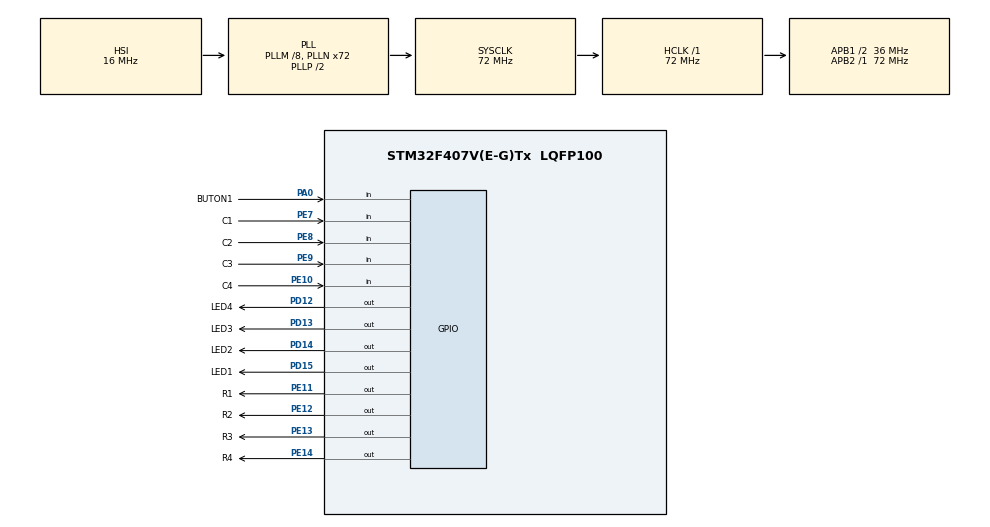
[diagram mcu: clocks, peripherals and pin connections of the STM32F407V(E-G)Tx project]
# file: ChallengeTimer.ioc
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Mcu.Family=STM32F4
Mcu.Name=STM32F407V(E-G)Tx
Mcu.Package=LQFP100
NVIC.PriorityGroup=NVIC_PRIORITYGROUP_4
NVIC.TIM2_IRQn=true\:0\:0\:false\:false\:true\:true\:true\:true
PA0-WKUP.GPIO_Label=BUTON1
PA0-WKUP.Signal=GPIO_Input
PA13.Mode=Serial_Wire
PA13.Signal=SYS_JTMS-SWDIO
PA14.Mode=Serial_Wire
PA14.Signal=SYS_JTCK-SWCLK
PD12.GPIO_Label=LED4
PD12.GPIO_Speed=GPIO_SPEED_FREQ_MEDIUM
PD12.Signal=GPIO_Output
PD13.GPIO_Label=LED3
PD13.GPIO_Speed=GPIO_SPEED_FREQ_MEDIUM
PD13.Signal=GPIO_Output
PD14.GPIO_Label=LED2
PD14.GPIO_Speed=GPIO_SPEED_FREQ_MEDIUM
PD14.Signal=GPIO_Output
PD15.GPIO_Label=LED1
PD15.GPIO_Speed=GPIO_SPEED_FREQ_MEDIUM
PD15.Signal=GPIO_Output
PE10.GPIO_Label=C4
PE10.GPIO_PuPd=GPIO_PULLDOWN
PE10.Signal=GPIO_Input
PE11.GPIO_Label=R1
PE11.GPIO_Speed=GPIO_SPEED_FREQ_MEDIUM
PE11.Signal=GPIO_Output
PE12.GPIO_Label=R2
PE12.GPIO_Speed=GPIO_SPEED_FREQ_MEDIUM
PE12.Signal=GPIO_Output
PE13.GPIO_Label=R3
PE13.GPIO_Speed=GPIO_SPEED_FREQ_MEDIUM
PE13.Signal=GPIO_Output
PE14.GPIO_Label=R4
PE14.GPIO_Speed=GPIO_SPEED_FREQ_MEDIUM
PE14.Signal=GPIO_Output
PE7.GPIO_Label=C1
PE7.GPIO_PuPd=GPIO_PULLDOWN
PE7.Signal=GPIO_Input
PE8.GPIO_Label=C2
PE8.GPIO_PuPd=GPIO_PULLDOWN
PE8.Signal=GPIO_Input
PE9.GPIO_Label=C3
PE9.GPIO_PuPd=GPIO_PULLDOWN
PE9.Signal=GPIO_Input
PH0-OSC_IN.Mode=HSE-External-Oscillator
PH0-OSC_IN.Signal=RCC_OSC_IN
PH1-OSC_OUT.Mode=HSE-External-Oscillator
PH1-OSC_OUT.Signal=RCC_OSC_OUT
ProjectManager.HeapSize=0x200
ProjectManager.StackSize=0x400
ProjectManager.TargetToolchain=STM32CubeIDE
RCC.48MHZClocksFreq_Value=36000000
RCC.AHBFreq_Value=72000000
RCC.APB1CLKDivider=RCC_HCLK_DIV2
RCC.APB1Freq_Value=36000000
RCC.APB1TimFreq_Value=72000000
RCC.APB2Freq_Value=72000000
RCC.APB2TimFreq_Value=72000000
RCC.CortexFreq_Value=72000000
RCC.HCLKFreq_Value=72000000
RCC.HSE_VALUE=25000000
RCC.HSI_VALUE=16000000
RCC.LSE_VALUE=32768
RCC.PLLM=8
RCC.PLLN=72
RCC.SYSCLKFreq_VALUE=72000000
RCC.SYSCLKSource=RCC_SYSCLKSOURCE_PLLCLK
RCC.VCOOutputFreq_Value=144000000
TIM2.Period=1000-1
TIM2.Prescaler=7200-1
VP_TIM2_VS_ClockSourceINT.Mode=Internal
board=custom

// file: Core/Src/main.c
/* USER CODE BEGIN Header */
/**
 ******************************************************************************
 * @file           : main.c
 * @brief          : Main program body
 ******************************************************************************
 * @attention
 *
 * Copyright (c) 2025 STMicroelectronics.
 * All rights reserved.
 *
 * This software is licensed under terms that can be found in the LICENSE file
 * in the root directory of this software component.
 * If no LICENSE file comes with this software, it is provided AS-IS.
 *
 ******************************************************************************
 */
/* USER CODE END Header */
#include "main.h"

/* USER CODE BEGIN Includes */
#include "keypad.h"
#include "macro.h"
#include "timer.h"
#include "mission.h"

/* USER CODE END Includes */

TIM_HandleTypeDef htim2;

void SystemClock_Config(void);
static void MX_GPIO_Init(void);
static void MX_TIM2_Init(void);
/* USER CODE BEGIN PFP */

char Read_Keypad(void);

/* USER CODE END PFP */

/* USER CODE BEGIN 0 */
char pressed_key = '\0';

/* USER CODE END 0 */

int main(void)
{

	/* USER CODE BEGIN 1 */

	//int atis_butonu=0;
	//int button_state=0;

	/* USER CODE END 1 */

	/* MCU Configuration--------------------------------------------------------*/

	/* Reset of all peripherals, Initializes the Flash interface and the Systick. */
	HAL_Init();

	/* Configure the system clock */
	SystemClock_Config();

	/* Initialize all configured peripherals */
	MX_GPIO_Init();
	MX_TIM2_Init();
	/* USER CODE BEGIN 2 */

	HAL_TIM_Base_Start_IT(&htim2);

	/* USER CODE END 2 */

	/* Infinite loop */
	while (1)
	{

		/* USER CODE BEGIN 3 */

		setFlags();
		timerMissions();
		clearFlags();

	}
	/* USER CODE END 3 */
}

void SystemClock_Config(void)
{
	RCC_OscInitTypeDef RCC_OscInitStruct = {0};
	RCC_ClkInitTypeDef RCC_ClkInitStruct = {0};

	/** Configure the main internal regulator output voltage
	 */
	__HAL_RCC_PWR_CLK_ENABLE();
	__HAL_PWR_VOLTAGESCALING_CONFIG(PWR_REGULATOR_VOLTAGE_SCALE1);

	/** Initializes the RCC Oscillators according to the specified parameters
	 * in the RCC_OscInitTypeDef structure.
	 */
	RCC_OscInitStruct.OscillatorType = RCC_OSCILLATORTYPE_HSI;
	RCC_OscInitStruct.HSIState = RCC_HSI_ON;
	RCC_OscInitStruct.HSICalibrationValue = RCC_HSICALIBRATION_DEFAULT;
	RCC_OscInitStruct.PLL.PLLState = RCC_PLL_ON;
	RCC_OscInitStruct.PLL.PLLSource = RCC_PLLSOURCE_HSI;
	RCC_OscInitStruct.PLL.PLLM = 8;
	RCC_OscInitStruct.PLL.PLLN = 72;
	RCC_OscInitStruct.PLL.PLLP = RCC_PLLP_DIV2;
	RCC_OscInitStruct.PLL.PLLQ = 4;
	if (HAL_RCC_OscConfig(&RCC_OscInitStruct) != HAL_OK)
	{
		Error_Handler();
	}

	/** Initializes the CPU, AHB and APB buses clocks
	 */
	RCC_ClkInitStruct.ClockType = RCC_CLOCKTYPE_HCLK|RCC_CLOCKTYPE_SYSCLK
			|RCC_CLOCKTYPE_PCLK1|RCC_CLOCKTYPE_PCLK2;
	RCC_ClkInitStruct.SYSCLKSource = RCC_SYSCLKSOURCE_PLLCLK;
	RCC_ClkInitStruct.AHBCLKDivider = RCC_SYSCLK_DIV1;
	RCC_ClkInitStruct.APB1CLKDivider = RCC_HCLK_DIV2;
	RCC_ClkInitStruct.APB2CLKDivider = RCC_HCLK_DIV1;

	if (HAL_RCC_ClockConfig(&RCC_ClkInitStruct, FLASH_LATENCY_2) != HAL_OK)
	{
		Error_Handler();
	}
}

static void MX_TIM2_Init(void)
{

	TIM_ClockConfigTypeDef sClockSourceConfig = {0};
	TIM_MasterConfigTypeDef sMasterConfig = {0};

	htim2.Instance = TIM2;
	htim2.Init.Prescaler = 7200-1;
	htim2.Init.CounterMode = TIM_COUNTERMODE_UP;
	htim2.Init.Period = 1000-1;
	htim2.Init.ClockDivision = TIM_CLOCKDIVISION_DIV1;
	htim2.Init.AutoReloadPreload = TIM_AUTORELOAD_PRELOAD_DISABLE;
	if (HAL_TIM_Base_Init(&htim2) != HAL_OK)
	{
		Error_Handler();
	}
	sClockSourceConfig.ClockSource = TIM_CLOCKSOURCE_INTERNAL;
	if (HAL_TIM_ConfigClockSource(&htim2, &sClockSourceConfig) != HAL_OK)
	{
		Error_Handler();
	}
	sMasterConfig.MasterOutputTrigger = TIM_TRGO_RESET;
	sMasterConfig.MasterSlaveMode = TIM_MASTERSLAVEMODE_DISABLE;
	if (HAL_TIMEx_MasterConfigSynchronization(&htim2, &sMasterConfig) != HAL_OK)
	{
		Error_Handler();
	}

}

static void MX_GPIO_Init(void)
{
	GPIO_InitTypeDef GPIO_InitStruct = {0};

	/* GPIO Ports Clock Enable */
	__HAL_RCC_GPIOH_CLK_ENABLE();
	__HAL_RCC_GPIOA_CLK_ENABLE();
	__HAL_RCC_GPIOE_CLK_ENABLE();
	__HAL_RCC_GPIOD_CLK_ENABLE();

	/*Configure GPIO pin Output Level */
	HAL_GPIO_WritePin(GPIOE, R1_Pin|R2_Pin|R3_Pin|R4_Pin, GPIO_PIN_RESET);

	/*Configure GPIO pin Output Level */
	HAL_GPIO_WritePin(GPIOD, LED4_Pin|LED3_Pin|LED2_Pin|LED1_Pin, GPIO_PIN_RESET);

	/*Configure GPIO pin : BUTON1_Pin */
	GPIO_InitStruct.Pin = BUTON1_Pin;
	GPIO_InitStruct.Mode = GPIO_MODE_INPUT;
	GPIO_InitStruct.Pull = GPIO_NOPULL;
	HAL_GPIO_Init(BUTON1_GPIO_Port, &GPIO_InitStruct);

	/*Configure GPIO pins : C1_Pin C2_Pin C3_Pin C4_Pin */
	GPIO_InitStruct.Pin = C1_Pin|C2_Pin|C3_Pin|C4_Pin;
	GPIO_InitStruct.Mode = GPIO_MODE_INPUT;
	GPIO_InitStruct.Pull = GPIO_PULLDOWN;
	HAL_GPIO_Init(GPIOE, &GPIO_InitStruct);

	/*Configure GPIO pins : R1_Pin R2_Pin R3_Pin R4_Pin */
	GPIO_InitStruct.Pin = R1_Pin|R2_Pin|R3_Pin|R4_Pin;
	GPIO_InitStruct.Mode = GPIO_MODE_OUTPUT_PP;
	GPIO_InitStruct.Pull = GPIO_NOPULL;
	GPIO_InitStruct.Speed = GPIO_SPEED_FREQ_MEDIUM;
	HAL_GPIO_Init(GPIOE, &GPIO_InitStruct);

	/*Configure GPIO pins : LED4_Pin LED3_Pin LED2_Pin LED1_Pin */
	GPIO_InitStruct.Pin = LED4_Pin|LED3_Pin|LED2_Pin|LED1_Pin;
	GPIO_InitStruct.Mode = GPIO_MODE_OUTPUT_PP;
	GPIO_InitStruct.Pull = GPIO_NOPULL;
	GPIO_InitStruct.Speed = GPIO_SPEED_FREQ_MEDIUM;
	HAL_GPIO_Init(GPIOD, &GPIO_InitStruct);

}

void Error_Handler(void)
{
	__disable_irq();
	while (1)
	{
	}
}
